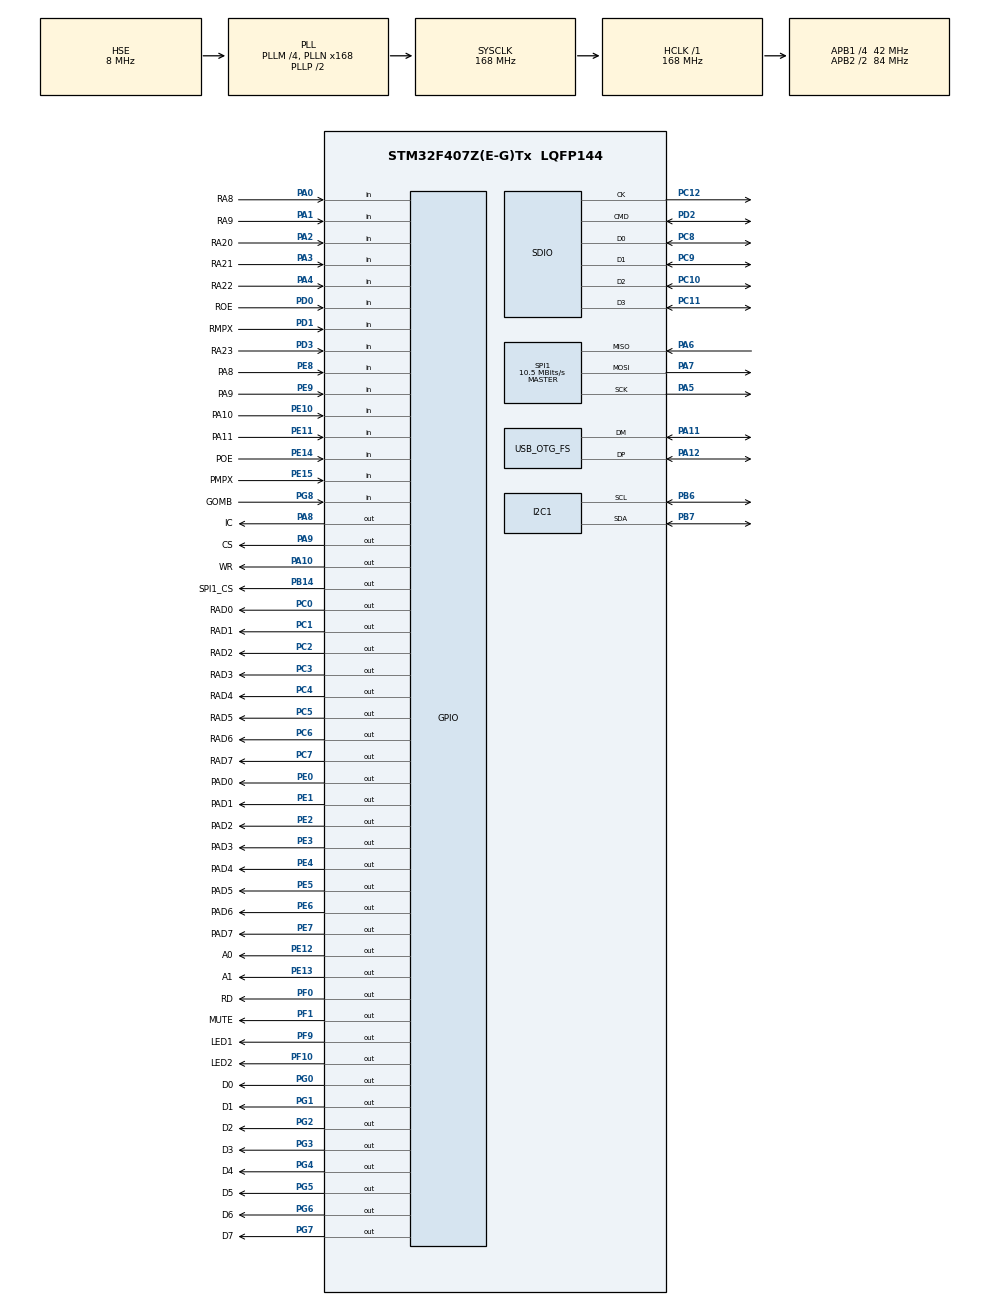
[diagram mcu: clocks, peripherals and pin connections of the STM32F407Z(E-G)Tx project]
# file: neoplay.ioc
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FATFS._MAX_SS=4096
FATFS._USE_LFN=2
I2C1.DutyCycle=I2C_DUTYCYCLE_2
I2C1.I2C_Mode=I2C_Fast
Mcu.Family=STM32F4
Mcu.Name=STM32F407Z(E-G)Tx
Mcu.Package=LQFP144
NVIC.OTG_FS_IRQn=true\:0\:0\:false\:false\:true\:false\:true
NVIC.PriorityGroup=NVIC_PRIORITYGROUP_4
NVIC.TIM6_DAC_IRQn=true\:0\:0\:false\:false\:true\:true\:true
PA0-WKUP.GPIO_Label=RA8
PA0-WKUP.Signal=GPIO_Input
PA1.GPIO_Label=RA9
PA1.Signal=GPIO_Input
PA10.GPIO_Label=WR
PA10.Signal=GPIO_Output
PA11.Mode=Device_Only
PA11.Signal=USB_OTG_FS_DM
PA12.Mode=Device_Only
PA12.Signal=USB_OTG_FS_DP
PA13.Mode=JTAG_5_pins
PA13.Signal=SYS_JTMS-SWDIO
PA14.Mode=JTAG_5_pins
PA14.Signal=SYS_JTCK-SWCLK
PA15.Mode=JTAG_5_pins
PA15.Signal=SYS_JTDI
PA2.GPIO_Label=RA20
PA2.Signal=GPIO_Input
PA3.GPIO_Label=RA21
PA3.Signal=GPIO_Input
PA4.GPIO_Label=RA22
PA4.Signal=GPIO_Input
PA5.Mode=Full_Duplex_Master
PA5.Signal=SPI1_SCK
PA6.Mode=Full_Duplex_Master
PA6.Signal=SPI1_MISO
PA7.Mode=Full_Duplex_Master
PA7.Signal=SPI1_MOSI
PA8.GPIO_Label=IC
PA8.Signal=GPIO_Output
PA9.GPIO_Label=CS
PA9.Signal=GPIO_Output
PB14.GPIO_Label=SPI1_CS
PB14.Signal=GPIO_Output
PB3.Mode=JTAG_5_pins
PB3.Signal=SYS_JTDO-SWO
PB4.Mode=JTAG_5_pins
PB4.Signal=SYS_JTRST
PB6.GPIO_Pu=GPIO_PULLUP
PB6.Mode=I2C
PB6.Signal=I2C1_SCL
PB7.GPIO_Pu=GPIO_PULLUP
PB7.Mode=I2C
PB7.Signal=I2C1_SDA
PC0.GPIO_Label=RAD0
PC0.Signal=GPIO_Output
PC1.GPIO_Label=RAD1
PC1.Signal=GPIO_Output
PC10.GPIO_PuPd=GPIO_PULLUP
PC10.Mode=SD_4_bits_Wide_bus
PC10.Signal=SDIO_D2
PC11.GPIO_PuPd=GPIO_PULLUP
PC11.Mode=SD_4_bits_Wide_bus
PC11.Signal=SDIO_D3
PC12.GPIO_PuPd=GPIO_NOPULL
PC12.Mode=SD_4_bits_Wide_bus
PC12.Signal=SDIO_CK
PC14-OSC32_IN.Mode=LSE-External-Oscillator
PC14-OSC32_IN.Signal=RCC_OSC32_IN
PC15-OSC32_OUT.Mode=LSE-External-Oscillator
PC15-OSC32_OUT.Signal=RCC_OSC32_OUT
PC2.GPIO_Label=RAD2
PC2.Signal=GPIO_Output
PC3.GPIO_Label=RAD3
PC3.Signal=GPIO_Output
PC4.GPIO_Label=RAD4
PC4.Signal=GPIO_Output
PC5.GPIO_Label=RAD5
PC5.Signal=GPIO_Output
PC6.GPIO_Label=RAD6
PC6.Signal=GPIO_Output
PC7.GPIO_Label=RAD7
PC7.Signal=GPIO_Output
PC8.GPIO_PuPd=GPIO_PULLUP
PC8.Mode=SD_4_bits_Wide_bus
PC8.Signal=SDIO_D0
PC9.GPIO_PuPd=GPIO_PULLUP
PC9.Mode=SD_4_bits_Wide_bus
PC9.Signal=SDIO_D1
PD0.GPIO_Label=ROE
PD0.Signal=GPIO_Input
PD1.GPIO_Label=RMPX
PD1.Signal=GPIO_Input
PD2.GPIO_PuPd=GPIO_PULLUP
PD2.Mode=SD_4_bits_Wide_bus
PD2.Signal=SDIO_CMD
PD3.GPIO_Label=RA23
PD3.Signal=GPIO_Input
PE0.GPIO_Label=PAD0
PE0.Signal=GPIO_Output
PE1.GPIO_Label=PAD1
PE1.Signal=GPIO_Output
PE10.GPIO_Label=PA10
PE10.Signal=GPIO_Input
PE11.GPIO_Label=PA11
PE11.Signal=GPIO_Input
PE12.GPIO_Label=A0
PE12.Signal=GPIO_Output
PE13.GPIO_Label=A1
PE13.Signal=GPIO_Output
PE14.GPIO_Label=POE
PE14.Signal=GPIO_Input
PE15.GPIO_Label=PMPX
PE15.Signal=GPIO_Input
PE2.GPIO_Label=PAD2
PE2.Signal=GPIO_Output
PE3.GPIO_Label=PAD3
PE3.Signal=GPIO_Output
PE4.GPIO_Label=PAD4
PE4.Signal=GPIO_Output
PE5.GPIO_Label=PAD5
PE5.Signal=GPIO_Output
PE6.GPIO_Label=PAD6
PE6.Signal=GPIO_Output
PE7.GPIO_Label=PAD7
PE7.Signal=GPIO_Output
PE8.GPIO_Label=PA8
PE8.Signal=GPIO_Input
PE9.GPIO_Label=PA9
PE9.Signal=GPIO_Input
PF0.GPIO_Label=RD
PF0.Signal=GPIO_Output
PF1.GPIO_Label=MUTE
PF1.GPIO_PuPd=GPIO_PULLUP
PF1.PinState=GPIO_PIN_SET
PF1.Signal=GPIO_Output
PF10.GPIO_Label=LED2
PF10.PinState=GPIO_PIN_SET
PF10.Signal=GPIO_Output
PF9.GPIO_Label=LED1
PF9.GPIO_PuPd=GPIO_NOPULL
PF9.PinState=GPIO_PIN_SET
PF9.Signal=GPIO_Output
PG0.GPIO_Label=D0
PG0.Signal=GPIO_Output
PG1.GPIO_Label=D1
PG1.Signal=GPIO_Output
PG2.GPIO_Label=D2
PG2.Signal=GPIO_Output
PG3.GPIO_Label=D3
PG3.Signal=GPIO_Output
PG4.GPIO_Label=D4
PG4.Signal=GPIO_Output
PG5.GPIO_Label=D5
PG5.Signal=GPIO_Output
PG6.GPIO_Label=D6
PG6.Signal=GPIO_Output
PG7.GPIO_Label=D7
PG7.Signal=GPIO_Output
PG8.GPIO_Label=GOMB
PG8.Signal=GPIO_Input
PH0-OSC_IN.Mode=HSE-External-Oscillator
PH0-OSC_IN.Signal=RCC_OSC_IN
PH1-OSC_OUT.Mode=HSE-External-Oscillator
PH1-OSC_OUT.Signal=RCC_OSC_OUT
ProjectManager.HeapSize=0x200
ProjectManager.StackSize=0x400
ProjectManager.TargetToolchain=STM32CubeIDE
RCC.48MHZClocksFreq_Value=48000000
RCC.AHBFreq_Value=168000000
RCC.APB1CLKDivider=RCC_HCLK_DIV4
RCC.APB1Freq_Value=42000000
RCC.APB1TimFreq_Value=84000000
RCC.APB2CLKDivider=RCC_HCLK_DIV2
RCC.APB2Freq_Value=84000000
RCC.APB2TimFreq_Value=168000000
RCC.CortexFreq_Value=168000000
RCC.HCLKFreq_Value=168000000
RCC.HSE_VALUE=8000000
RCC.HSI_VALUE=16000000
RCC.PLLM=4
RCC.PLLN=168
RCC.PLLQ=7
RCC.SYSCLKFreq_VALUE=168000000
RCC.SYSCLKSource=RCC_SYSCLKSOURCE_PLLCLK
RCC.VCOOutputFreq_Value=336000000
SPI1.BaudRatePrescaler=SPI_BAUDRATEPRESCALER_8
SPI1.CalculateBaudRate=10.5 MBits/s
SPI1.Direction=SPI_DIRECTION_2LINES
SPI1.Mode=SPI_MODE_MASTER
SPI1.VirtualType=VM_MASTER
TIM6.Period=167
USB_DEVICE.CLASS_NAME_FS=CDC
USB_DEVICE.VirtualMode-CDC_FS=Cdc
USB_DEVICE.VirtualModeFS=Cdc_FS
USB_OTG_FS.VirtualMode=Device_Only
VP_FATFS_VS_SDIO.Mode=SDIO
VP_TIM6_VS_ClockSourceINT.Mode=Enable_Timer
VP_USB_DEVICE_VS_USB_DEVICE_CDC_FS.Mode=CDC_FS
board=custom

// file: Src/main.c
/* USER CODE BEGIN Header */
/******************************************************
 * file name:   main.c
 * title:       Neo Geo VGM Player
 * autor:       DPTP System
 * date:        2024.02.03.
 * email:       don_peter[kukac]freemail[pont]hu
 * device:      STM32
 * platform:    C Code, STM32CubeIDE
 * MCU:         STM32F407ZET6
******************************************************/
/* USER CODE END Header */
#include "main.h"
#include "fatfs.h"
#include "usb_device.h"
#include "gpio.h"

I2C_HandleTypeDef hi2c1;

SD_HandleTypeDef hsd;

SPI_HandleTypeDef hspi1;

TIM_HandleTypeDef htim6;

/* USER CODE BEGIN PV */

uint16_t timer_1us_u16 = 0;

/* USER CODE END PV */

void SystemClock_Config(void);
static void MX_GPIO_Init(void);
static void MX_SDIO_SD_Init(void);
static void MX_I2C1_Init(void);
static void MX_SPI1_Init(void);
static void MX_TIM6_Init(void);

int main(void)
{

  /* MCU Configuration--------------------------------------------------------*/

  /* Reset of all peripherals, Initializes the Flash interface and the Systick. */
  HAL_Init();

  /* Configure the system clock */
  SystemClock_Config();

  /* Initialize all configured peripherals */
  MX_GPIO_Init();
  MX_SDIO_SD_Init();
  MX_FATFS_Init();
  MX_USB_DEVICE_Init();
  MX_I2C1_Init();
  MX_SPI1_Init();
  MX_TIM6_Init();
  /* USER CODE BEGIN 2 */

  // Start timer (1us interrupt start)
  HAL_TIM_Base_Start_IT(&htim6);

  /* USER CODE END 2 */

  /* Infinite loop */
  /* USER CODE BEGIN WHILE */

  // GPIO driver init
  gpio_init_pins();
  led0_out_pst->set(led0_out_pst, 0);
  led1_out_pst->set(led1_out_pst, 0);

  while (1)
  {

	  // 1 uS
	  if(timer_1us_u16)
	  {
		  timer_1us_u16 = 0;
		  HAL_GPIO_TogglePin(LED1_GPIO_Port, LED1_Pin);
	  }

    /* USER CODE END WHILE */

  }
}

void SystemClock_Config(void)
{
  RCC_OscInitTypeDef RCC_OscInitStruct = {0};
  RCC_ClkInitTypeDef RCC_ClkInitStruct = {0};

  /** Configure the main internal regulator output voltage
  */
  __HAL_RCC_PWR_CLK_ENABLE();
  __HAL_PWR_VOLTAGESCALING_CONFIG(PWR_REGULATOR_VOLTAGE_SCALE1);
  /** Initializes the RCC Oscillators according to the specified parameters
  * in the RCC_OscInitTypeDef structure.
  */
  RCC_OscInitStruct.OscillatorType = RCC_OSCILLATORTYPE_HSE;
  RCC_OscInitStruct.HSEState = RCC_HSE_ON;
  RCC_OscInitStruct.PLL.PLLState = RCC_PLL_ON;
  RCC_OscInitStruct.PLL.PLLSource = RCC_PLLSOURCE_HSE;
  RCC_OscInitStruct.PLL.PLLM = 4;
  RCC_OscInitStruct.PLL.PLLN = 168;
  RCC_OscInitStruct.PLL.PLLP = RCC_PLLP_DIV2;
  RCC_OscInitStruct.PLL.PLLQ = 7;
  if (HAL_RCC_OscConfig(&RCC_OscInitStruct) != HAL_OK)
  {
    Error_Handler();
  }
  /** Initializes the CPU, AHB and APB buses clocks
  */
  RCC_ClkInitStruct.ClockType = RCC_CLOCKTYPE_HCLK|RCC_CLOCKTYPE_SYSCLK
                              |RCC_CLOCKTYPE_PCLK1|RCC_CLOCKTYPE_PCLK2;
  RCC_ClkInitStruct.SYSCLKSource = RCC_SYSCLKSOURCE_PLLCLK;
  RCC_ClkInitStruct.AHBCLKDivider = RCC_SYSCLK_DIV1;
  RCC_ClkInitStruct.APB1CLKDivider = RCC_HCLK_DIV4;
  RCC_ClkInitStruct.APB2CLKDivider = RCC_HCLK_DIV2;

  if (HAL_RCC_ClockConfig(&RCC_ClkInitStruct, FLASH_LATENCY_5) != HAL_OK)
  {
    Error_Handler();
  }
}

static void MX_I2C1_Init(void)
{

  hi2c1.Instance = I2C1;
  hi2c1.Init.ClockSpeed = 400000;
  hi2c1.Init.DutyCycle = I2C_DUTYCYCLE_2;
  hi2c1.Init.OwnAddress1 = 0;
  hi2c1.Init.AddressingMode = I2C_ADDRESSINGMODE_7BIT;
  hi2c1.Init.DualAddressMode = I2C_DUALADDRESS_DISABLE;
  hi2c1.Init.OwnAddress2 = 0;
  hi2c1.Init.GeneralCallMode = I2C_GENERALCALL_DISABLE;
  hi2c1.Init.NoStretchMode = I2C_NOSTRETCH_DISABLE;
  if (HAL_I2C_Init(&hi2c1) != HAL_OK)
  {
    Error_Handler();
  }

}

static void MX_SDIO_SD_Init(void)
{

  hsd.Instance = SDIO;
  hsd.Init.ClockEdge = SDIO_CLOCK_EDGE_RISING;
  hsd.Init.ClockBypass = SDIO_CLOCK_BYPASS_DISABLE;
  hsd.Init.ClockPowerSave = SDIO_CLOCK_POWER_SAVE_DISABLE;
  hsd.Init.BusWide = SDIO_BUS_WIDE_1B;
  hsd.Init.HardwareFlowControl = SDIO_HARDWARE_FLOW_CONTROL_DISABLE;
  hsd.Init.ClockDiv = 0;

}

static void MX_SPI1_Init(void)
{

  /* SPI1 parameter configuration*/
  hspi1.Instance = SPI1;
  hspi1.Init.Mode = SPI_MODE_MASTER;
  hspi1.Init.Direction = SPI_DIRECTION_2LINES;
  hspi1.Init.DataSize = SPI_DATASIZE_8BIT;
  hspi1.Init.CLKPolarity = SPI_POLARITY_LOW;
  hspi1.Init.CLKPhase = SPI_PHASE_1EDGE;
  hspi1.Init.NSS = SPI_NSS_SOFT;
  hspi1.Init.BaudRatePrescaler = SPI_BAUDRATEPRESCALER_8;
  hspi1.Init.FirstBit = SPI_FIRSTBIT_MSB;
  hspi1.Init.TIMode = SPI_TIMODE_DISABLE;
  hspi1.Init.CRCCalculation = SPI_CRCCALCULATION_DISABLE;
  hspi1.Init.CRCPolynomial = 10;
  if (HAL_SPI_Init(&hspi1) != HAL_OK)
  {
    Error_Handler();
  }

}

static void MX_TIM6_Init(void)
{

  TIM_MasterConfigTypeDef sMasterConfig = {0};

  htim6.Instance = TIM6;
  htim6.Init.Prescaler = 0;
  htim6.Init.CounterMode = TIM_COUNTERMODE_UP;
  htim6.Init.Period = 167;
  htim6.Init.AutoReloadPreload = TIM_AUTORELOAD_PRELOAD_DISABLE;
  if (HAL_TIM_Base_Init(&htim6) != HAL_OK)
  {
    Error_Handler();
  }
  sMasterConfig.MasterOutputTrigger = TIM_TRGO_RESET;
  sMasterConfig.MasterSlaveMode = TIM_MASTERSLAVEMODE_DISABLE;
  if (HAL_TIMEx_MasterConfigSynchronization(&htim6, &sMasterConfig) != HAL_OK)
  {
    Error_Handler();
  }

}

static void MX_GPIO_Init(void)
{
  GPIO_InitTypeDef GPIO_InitStruct = {0};

  /* GPIO Ports Clock Enable */
  __HAL_RCC_GPIOE_CLK_ENABLE();
  __HAL_RCC_GPIOC_CLK_ENABLE();
  __HAL_RCC_GPIOF_CLK_ENABLE();
  __HAL_RCC_GPIOH_CLK_ENABLE();
  __HAL_RCC_GPIOA_CLK_ENABLE();
  __HAL_RCC_GPIOG_CLK_ENABLE();
  __HAL_RCC_GPIOB_CLK_ENABLE();
  __HAL_RCC_GPIOD_CLK_ENABLE();

  /*Configure GPIO pin Output Level */
  HAL_GPIO_WritePin(GPIOE, PAD2_Pin|PAD3_Pin|PAD4_Pin|PAD5_Pin
                          |PAD6_Pin|PAD7_Pin|A0_Pin|A1_Pin
                          |PAD0_Pin|PAD1_Pin, GPIO_PIN_RESET);

  /*Configure GPIO pin Output Level */
  HAL_GPIO_WritePin(RD_GPIO_Port, RD_Pin, GPIO_PIN_RESET);

  /*Configure GPIO pin Output Level */
  HAL_GPIO_WritePin(GPIOF, MUTE_Pin|LED1_Pin|LED2_Pin, GPIO_PIN_SET);

  /*Configure GPIO pin Output Level */
  HAL_GPIO_WritePin(GPIOC, RAD0_Pin|RAD1_Pin|RAD2_Pin|RAD3_Pin
                          |RAD4_Pin|RAD5_Pin|RAD6_Pin|RAD7_Pin, GPIO_PIN_RESET);

  /*Configure GPIO pin Output Level */
  HAL_GPIO_WritePin(GPIOG, D0_Pin|D1_Pin|D2_Pin|D3_Pin
                          |D4_Pin|D5_Pin|D6_Pin|D7_Pin, GPIO_PIN_RESET);

  /*Configure GPIO pin Output Level */
  HAL_GPIO_WritePin(SPI1_CS_GPIO_Port, SPI1_CS_Pin, GPIO_PIN_RESET);

  /*Configure GPIO pin Output Level */
  HAL_GPIO_WritePin(GPIOA, IC_Pin|CS_Pin|WR_Pin, GPIO_PIN_RESET);

  /*Configure GPIO pins : PAD2_Pin PAD3_Pin PAD4_Pin PAD5_Pin
                           PAD6_Pin PAD7_Pin A0_Pin A1_Pin
                           PAD0_Pin PAD1_Pin */
  GPIO_InitStruct.Pin = PAD2_Pin|PAD3_Pin|PAD4_Pin|PAD5_Pin
                          |PAD6_Pin|PAD7_Pin|A0_Pin|A1_Pin
                          |PAD0_Pin|PAD1_Pin;
  GPIO_InitStruct.Mode = GPIO_MODE_OUTPUT_PP;
  GPIO_InitStruct.Pull = GPIO_NOPULL;
  GPIO_InitStruct.Speed = GPIO_SPEED_FREQ_LOW;
  HAL_GPIO_Init(GPIOE, &GPIO_InitStruct);

  /*Configure GPIO pins : RD_Pin LED1_Pin LED2_Pin */
  GPIO_InitStruct.Pin = RD_Pin|LED1_Pin|LED2_Pin;
  GPIO_InitStruct.Mode = GPIO_MODE_OUTPUT_PP;
  GPIO_InitStruct.Pull = GPIO_NOPULL;
  GPIO_InitStruct.Speed = GPIO_SPEED_FREQ_LOW;
  HAL_GPIO_Init(GPIOF, &GPIO_InitStruct);

  /*Configure GPIO pin : MUTE_Pin */
  GPIO_InitStruct.Pin = MUTE_Pin;
  GPIO_InitStruct.Mode = GPIO_MODE_OUTPUT_PP;
  GPIO_InitStruct.Pull = GPIO_PULLUP;
  GPIO_InitStruct.Speed = GPIO_SPEED_FREQ_LOW;
  HAL_GPIO_Init(MUTE_GPIO_Port, &GPIO_InitStruct);

  /*Configure GPIO pins : RAD0_Pin RAD1_Pin RAD2_Pin RAD3_Pin
                           RAD4_Pin RAD5_Pin RAD6_Pin RAD7_Pin */
  GPIO_InitStruct.Pin = RAD0_Pin|RAD1_Pin|RAD2_Pin|RAD3_Pin
                          |RAD4_Pin|RAD5_Pin|RAD6_Pin|RAD7_Pin;
  GPIO_InitStruct.Mode = GPIO_MODE_OUTPUT_PP;
  GPIO_InitStruct.Pull = GPIO_NOPULL;
  GPIO_InitStruct.Speed = GPIO_SPEED_FREQ_LOW;
  HAL_GPIO_Init(GPIOC, &GPIO_InitStruct);

  /*Configure GPIO pins : RA8_Pin RA9_Pin RA20_Pin RA21_Pin
                           RA22_Pin */
  GPIO_InitStruct.Pin = RA8_Pin|RA9_Pin|RA20_Pin|RA21_Pin
                          |RA22_Pin;
  GPIO_InitStruct.Mode = GPIO_MODE_INPUT;
  GPIO_InitStruct.Pull = GPIO_NOPULL;
  HAL_GPIO_Init(GPIOA, &GPIO_InitStruct);

  /*Configure GPIO pins : D0_Pin D1_Pin D2_Pin D3_Pin
                           D4_Pin D5_Pin D6_Pin D7_Pin */
  GPIO_InitStruct.Pin = D0_Pin|D1_Pin|D2_Pin|D3_Pin
                          |D4_Pin|D5_Pin|D6_Pin|D7_Pin;
  GPIO_InitStruct.Mode = GPIO_MODE_OUTPUT_PP;
  GPIO_InitStruct.Pull = GPIO_NOPULL;
  GPIO_InitStruct.Speed = GPIO_SPEED_FREQ_LOW;
  HAL_GPIO_Init(GPIOG, &GPIO_InitStruct);

  /*Configure GPIO pins : PA8_Pin PA9_Pin PA10_Pin PA11_Pin
                           POE_Pin PMPX_Pin */
  GPIO_InitStruct.Pin = PA8_Pin|PA9_Pin|PA10_Pin|PA11_Pin
                          |POE_Pin|PMPX_Pin;
  GPIO_InitStruct.Mode = GPIO_MODE_INPUT;
  GPIO_InitStruct.Pull = GPIO_NOPULL;
  HAL_GPIO_Init(GPIOE, &GPIO_InitStruct);

  /*Configure GPIO pin : SPI1_CS_Pin */
  GPIO_InitStruct.Pin = SPI1_CS_Pin;
  GPIO_InitStruct.Mode = GPIO_MODE_OUTPUT_PP;
  GPIO_InitStruct.Pull = GPIO_NOPULL;
  GPIO_InitStruct.Speed = GPIO_SPEED_FREQ_LOW;
  HAL_GPIO_Init(SPI1_CS_GPIO_Port, &GPIO_InitStruct);

  /*Configure GPIO pin : GOMB_Pin */
  GPIO_InitStruct.Pin = GOMB_Pin;
  GPIO_InitStruct.Mode = GPIO_MODE_INPUT;
  GPIO_InitStruct.Pull = GPIO_NOPULL;
  HAL_GPIO_Init(GOMB_GPIO_Port, &GPIO_InitStruct);

  /*Configure GPIO pins : IC_Pin CS_Pin WR_Pin */
  GPIO_InitStruct.Pin = IC_Pin|CS_Pin|WR_Pin;
  GPIO_InitStruct.Mode = GPIO_MODE_OUTPUT_PP;
  GPIO_InitStruct.Pull = GPIO_NOPULL;
  GPIO_InitStruct.Speed = GPIO_SPEED_FREQ_LOW;
  HAL_GPIO_Init(GPIOA, &GPIO_InitStruct);

  /*Configure GPIO pins : ROE_Pin RMPX_Pin RA23_Pin */
  GPIO_InitStruct.Pin = ROE_Pin|RMPX_Pin|RA23_Pin;
  GPIO_InitStruct.Mode = GPIO_MODE_INPUT;
  GPIO_InitStruct.Pull = GPIO_NOPULL;
  HAL_GPIO_Init(GPIOD, &GPIO_InitStruct);

}

/* USER CODE BEGIN 4 */

// Callback: timer has rolled over
void HAL_TIM_PeriodElapsedCallback(TIM_HandleTypeDef *htim)
{
	// Check which version of the timer triggered this callback and toggle LED
	if (htim == &htim6 )
	{
		timer_1us_u16++;
	}
}

/* USER CODE END 4 */

void Error_Handler(void)
{
  __disable_irq();
  while (1)
  {
  }
}
